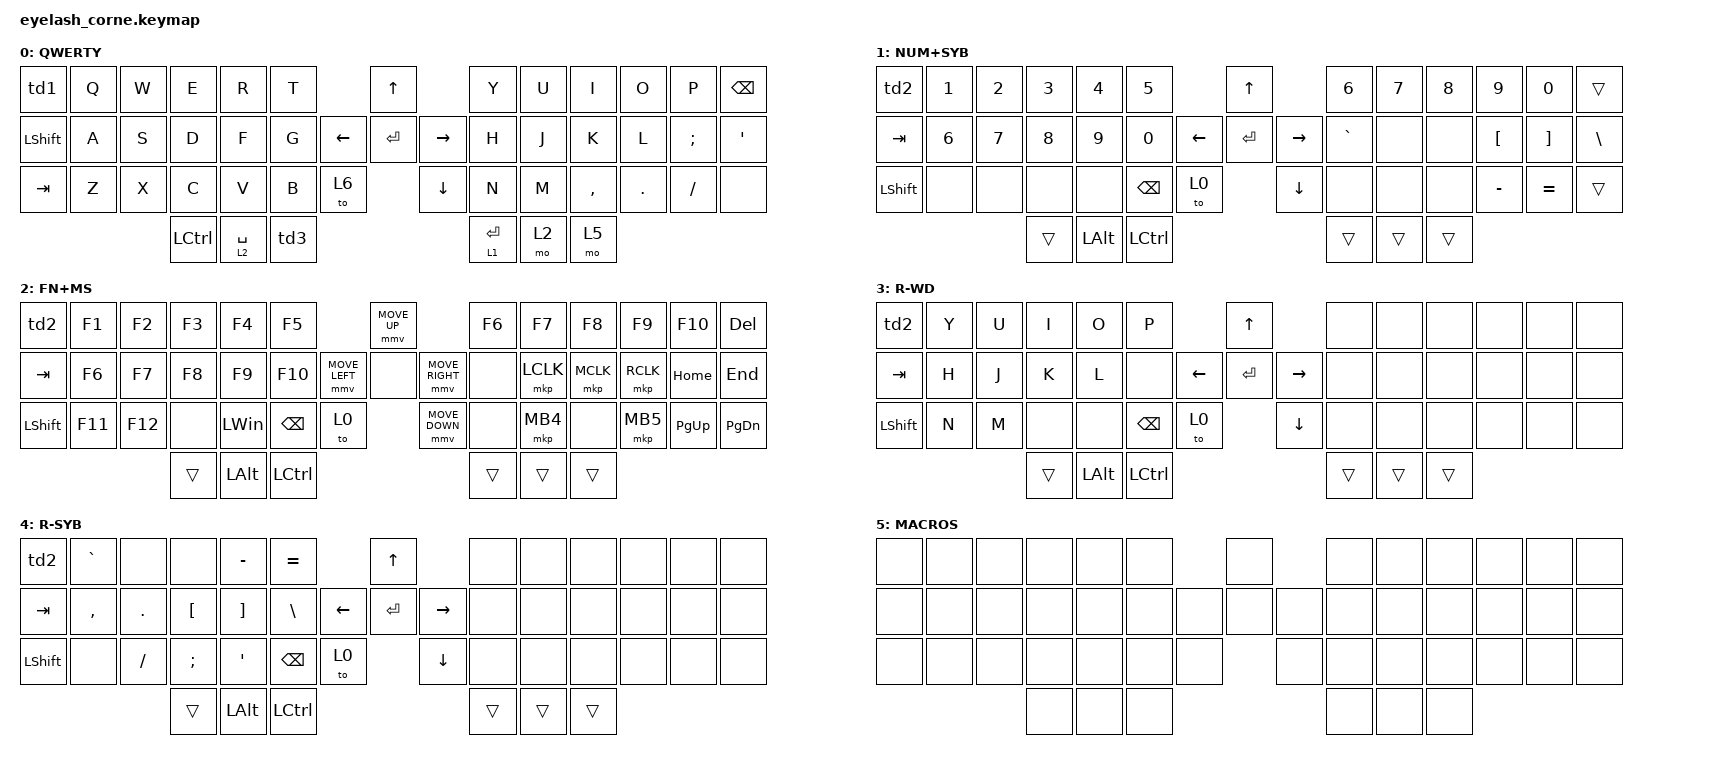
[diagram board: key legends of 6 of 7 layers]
#include <dt-bindings/zmk/mouse.h>
#include <input/processors.dtsi>
#include <behaviors.dtsi>
#include <dt-bindings/zmk/bt.h>
#include <dt-bindings/zmk/keys.h>
#include <dt-bindings/zmk/outputs.h>
#include <dt-bindings/zmk/pointing.h>
#include <dt-bindings/zmk/pointing.h>
#include <dt-bindings/zmk/pointing.h>
#include <dt-bindings/zmk/rgb.h>

/*

   &mmv_input_listener {
       input-processors = <&zip_xy_scaler 2 1>;
   };

   &msc_input_listener {
       input-processors = <&zip_xy_scaler 2 1>;
   };

 */

#define ZMK_MOUSE_DEFAULT_MOVE_VAL 1200  // 600
#define ZMK_MOUSE_DEFAULT_SCRL_VAL 20    // 10

/ {
    behaviors {
        td0: td0 {
            compatible = "zmk,behavior-tap-dance";
            display-name = "Shift/Caps Lock Tap Dance";
            #binding-cells = <0>;
            bindings = <&kp LEFT_SHIFT>, <&kp CAPS>;
        };

        td1: esc_r1_r2 {
            compatible = "zmk,behavior-tap-dance";
            display-name = "LESC/TO3/TO4";
            #binding-cells = <0>;
            bindings = <&kp ESC>, <&to 3>, <&to 4>;
        };

        td2: esc_to0 {
            compatible = "zmk,behavior-tap-dance";
            display-name = "LESC/TO0";
            #binding-cells = <0>;
            bindings = <&kp ESC>, <&to 0>, <&to 0>;
        };

        td3: alt_enter {
            compatible = "zmk,behavior-tap-dance";
            display-name = "LALT/ENTER";
            #binding-cells = <0>;
            bindings = <&kp LALT>, <&kp ENTER>;
        };
    };

    macros {
        zed_em_kay: zed_em_kay {
            compatible = "zmk,behavior-macro";
            #binding-cells = <0>;
            bindings =
                <&macro_press>,
                <&kp LSHFT>,
                <&macro_tap>,
                <&kp Z &kp M &kp K>,
                <&macro_release>,
                <&kp LSHFT>;
        };
    };

    rgb_encoder: rgb_encoder {
        compatible = "zmk,behavior-sensor-rotate";
        #sensor-binding-cells = <0>;
        bindings = <&rgb_ug RGB_BRI>, <&rgb_ug RGB_BRD>;
    };

    scroll_encoder: scroll_encoder {
        compatible = "zmk,behavior-sensor-rotate";
        #sensor-binding-cells = <0>;
        bindings = <&msc SCRL_DOWN>, <&msc SCRL_UP>;

        tap-ms = <30>;
    };

    keymap {
        compatible = "zmk,keymap";

        default_layer {
            display-name = "QWERTY";
            bindings = <
&td1            &kp Q  &kp W  &kp E        &kp R  &kp T                         &kp UP                &kp Y        &kp U  &kp I      &kp O    &kp P     &kp BSPC
&kp LEFT_SHIFT         &kp A  &kp S  &kp D        &kp F  &kp G               &kp LEFT  &kp ENTER  &kp RIGHT  &kp H        &kp J  &kp K      &kp L    &kp SEMI  &kp SQT
&kp TAB  &kp Z  &kp X  &kp C        &kp V  &kp B      &to 6              &kp DOWN              &kp N        &kp M  &kp COMMA  &kp DOT  &kp FSLH  &none
                              &kp LCTRL &lt 2 SPACE  &td3                                              &lt 1 ENTER  &mo 2  &mo 5
            >;

            sensor-bindings = <&scroll_encoder>;
        };

        number_symbol_layer {
            display-name = "NUM+SYB";
            bindings = <
&td2            &kp NUMBER_1  &kp NUMBER_2  &kp NUMBER_3  &kp NUMBER_4  &kp NUMBER_5                     &kp UP                &kp NUMBER_6  &kp NUMBER_7  &kp NUMBER_8  &kp NUMBER_9  &kp NUMBER_0  &trans
&kp TAB         &kp NUMBER_6  &kp NUMBER_7  &kp NUMBER_8  &kp NUMBER_9  &kp NUMBER_0           &kp LEFT  &kp ENTER  &kp RIGHT  &kp GRAVE     &none         &none         &kp LBKT      &kp RBKT      &kp BSLH
&kp LEFT_SHIFT  &none         &none         &none         &none         &kp BSPC      &to 0              &kp DOWN              &none         &none         &none         &kp MINUS     &kp EQUAL     &trans
                                            &trans        &kp LALT      &kp LCTRL                                              &trans        &trans        &trans
            >;

            sensor-bindings = <&scroll_encoder>;
        };

        fn_mouse_layer {
            display-name = "FN+MS";
            bindings = <
&td2            &kp F1   &kp F2   &kp F3  &kp F4        &kp F5                              &mmv MOVE_UP                     &kp F6  &kp F7     &kp F8     &kp F9     &kp F10    &kp DEL
&kp TAB         &kp F6   &kp F7   &kp F8  &kp F9        &kp F10             &mmv MOVE_LEFT  &none           &mmv MOVE_RIGHT  &none   &mkp LCLK  &mkp MCLK  &mkp RCLK  &kp HOME   &kp END
&kp LEFT_SHIFT  &kp F11  &kp F12  &none   &kp LEFT_WIN  &kp BSPC   &to 0                    &mmv MOVE_DOWN                   &none   &mkp MB4   &none      &mkp MB5   &kp PG_UP  &kp PG_DN
                                  &trans  &kp LALT      &kp LCTRL                                                            &trans  &trans     &trans
            >;

            sensor-bindings = <&scroll_encoder>;
        };

        right_cp1 {
            display-name = "R-WD";
            bindings = <
&td2            &kp Y  &kp U  &kp I   &kp O     &kp P                         &kp UP                &none   &none   &none   &none  &none  &none
&kp TAB         &kp H  &kp J  &kp K   &kp L     &none               &kp LEFT  &kp ENTER  &kp RIGHT  &none   &none   &none   &none  &none  &none
&kp LEFT_SHIFT  &kp N  &kp M  &none   &none     &kp BSPC   &to 0              &kp DOWN              &none   &none   &none   &none  &none  &none
                              &trans  &kp LALT  &kp LCTRL                                           &trans  &trans  &trans
            >;

            sensor-bindings = <&scroll_encoder>;
        };

        right_cp2 {
            display-name = "R-SYB";
            bindings = <
&td2            &kp GRAVE  &none     &none     &kp MINUS  &kp EQUAL                     &kp UP                &none   &none   &none   &none  &none  &none
&kp TAB         &kp COMMA  &kp DOT   &kp LBKT  &kp RBKT   &kp BSLH            &kp LEFT  &kp ENTER  &kp RIGHT  &none   &none   &none   &none  &none  &none
&kp LEFT_SHIFT  &none      &kp FSLH  &kp SEMI  &kp SQT    &kp BSPC   &to 0              &kp DOWN              &none   &none   &none   &none  &none  &none
                                     &trans    &kp LALT   &kp LCTRL                                           &trans  &trans  &trans
            >;

            sensor-bindings = <&scroll_encoder>;
        };

        macors_layers {
            display-name = "MACROS";
            bindings = <
&none  &none  &none  &none  &none  &none                  &none         &none  &none  &none  &none  &none  &none
&none  &none  &none  &none  &none  &none           &none  &none  &none  &none  &none  &none  &none  &none  &none
&none  &none  &none  &none  &none  &none  &none           &none         &none  &none  &none  &none  &none  &none
                     &none  &none  &none                                &none  &none  &none
            >;

            sensor-bindings = <&scroll_encoder>;
        };

        setting_layer {
            display-name = "SET";
            bindings = <
&td2            &bt BT_CLR_ALL   &bt BT_SEL 0     &bt BT_SEL 1     &bt BT_SEL 2     &bt BT_SEL 3                     &none         &studio_unlock   &none       &none           &none            &none  &none
&out OUT_USB    &out OUT_BLE     &sys_reset       &bootloader      &none            &none                     &none  &none  &none  &bootloader      &sys_reset  &kp SCROLLLOCK  &kp PAUSE_BREAK  &none  &none
&rgb_ug RGB_ON  &rgb_ug RGB_OFF  &rgb_ug RGB_EFF  &rgb_ug RGB_EFR  &rgb_ug RGB_SPI  &rgb_ug RGB_BRI  &none           &none         &rgb_ug RGB_BRD  &none       &none           &none            &none  &none
                                                  &none            &none            &none                                          &none            &none
            >;

            sensor-bindings = <&scroll_encoder>;
        };
    };
};
